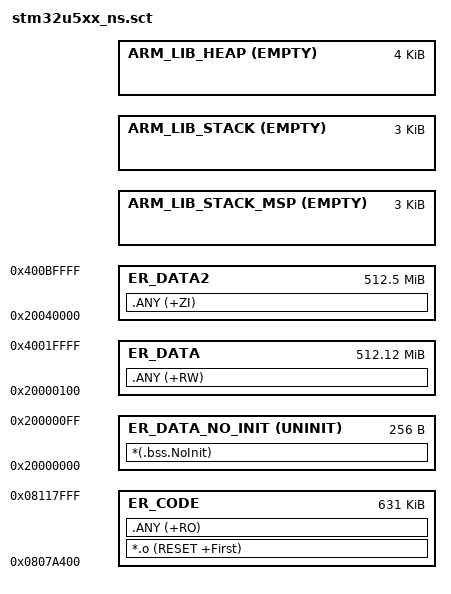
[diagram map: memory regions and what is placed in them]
#! armclang -E --target=arm-arm-none-eabi -mcpu=cortex-m33 -xc
/*
 * Copyright (c) 2017-2018 ARM Limited
 *
 * Licensed under the Apache License, Version 2.0 (the "License");
 * you may not use this file except in compliance with the License.
 * You may obtain a copy of the License at
 *
 *     http://www.apache.org/licenses/LICENSE-2.0
 *
 * Unless required by applicable law or agreed to in writing, software
 * distributed under the License is distributed on an "AS IS" BASIS,
 * WITHOUT WARRANTIES OR CONDITIONS OF ANY KIND, either express or implied.
 * See the License for the specific language governing permissions and
 * limitations under the License.
 */

#define NS_CODE_START           0x0807A400
#define NS_CODE_SIZE            0x0009DC00
#define NS_DATA_START           0x20000000
#define NS_NO_INIT_DATA_SIZE    0x00000100
#define NS_DATA_SIZE            0x20020000
#define NS_DATA2_START          0x20040000
#define NS_DATA2_SIZE           0x20080000
#define NS_HEAP_SIZE            0x00001000
#define NS_MSP_STACK_SIZE       0x00000C00
#define NS_PSP_STACK_SIZE       0x00000C00

LR_CODE NS_CODE_START {
    ER_CODE NS_CODE_START NS_CODE_SIZE {
        *.o (RESET +First)
        .ANY (+RO)
    }

    ER_DATA_NO_INIT NS_DATA_START UNINIT NS_NO_INIT_DATA_SIZE {
        *(.bss.NoInit)
    }
    ER_DATA (NS_DATA_START + NS_NO_INIT_DATA_SIZE) (NS_DATA_SIZE - NS_NO_INIT_DATA_SIZE) {
        .ANY (+RW)
    }
    ER_DATA2 NS_DATA2_START NS_DATA2_SIZE {
        .ANY (+ZI)
    }
    /* MSP */
    ARM_LIB_STACK_MSP +0 ALIGN 32 EMPTY NS_MSP_STACK_SIZE {
    }

    /* PSP */
    ARM_LIB_STACK +0 ALIGN 32 EMPTY NS_PSP_STACK_SIZE {
    }

    ARM_LIB_HEAP +0 ALIGN 8 EMPTY NS_HEAP_SIZE {
    }
}

